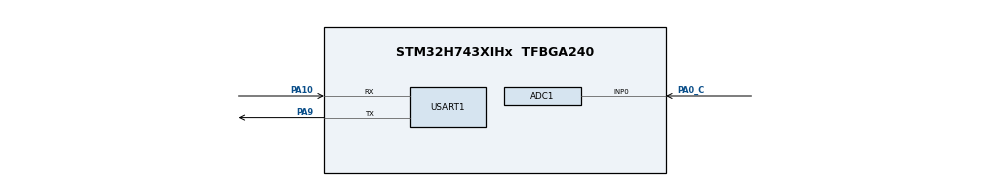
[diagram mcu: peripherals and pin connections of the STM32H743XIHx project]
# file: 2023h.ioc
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ADC1.Channel-1\#ChannelRegularConversion=ADC_CHANNEL_0
ADC1.ConversionDataManagement=ADC_CONVERSIONDATA_DMA_CIRCULAR
ADC1.ExternalTrigConv=ADC_EXTERNALTRIG_T6_TRGO
ADC1.NbrOfConversionFlag=1
ADC1.OffsetNumber-1\#ChannelRegularConversion=ADC_OFFSET_NONE
ADC1.OffsetSignedSaturation-1\#ChannelRegularConversion=DISABLE
ADC1.Overrun=ADC_OVR_DATA_OVERWRITTEN
ADC1.Rank-1\#ChannelRegularConversion=1
ADC1.SamplingTime-1\#ChannelRegularConversion=ADC_SAMPLETIME_1CYCLE_5
ADC1.master=1
CORTEX_M7.default_mode_Activation=1
Dma.ADC1.0.Direction=DMA_PERIPH_TO_MEMORY
Dma.ADC1.0.EventEnable=DISABLE
Dma.ADC1.0.FIFOMode=DMA_FIFOMODE_DISABLE
Dma.ADC1.0.Instance=DMA1_Stream0
Dma.ADC1.0.MemDataAlignment=DMA_MDATAALIGN_HALFWORD
Dma.ADC1.0.MemInc=DMA_MINC_ENABLE
Dma.ADC1.0.Mode=DMA_CIRCULAR
Dma.ADC1.0.PeriphDataAlignment=DMA_PDATAALIGN_HALFWORD
Dma.ADC1.0.PeriphInc=DMA_PINC_DISABLE
Dma.ADC1.0.Polarity=HAL_DMAMUX_REQ_GEN_RISING
Dma.ADC1.0.Priority=DMA_PRIORITY_LOW
Dma.ADC1.0.RequestNumber=1
Dma.ADC1.0.SignalID=NONE
Dma.ADC1.0.SyncEnable=DISABLE
Dma.ADC1.0.SyncPolarity=HAL_DMAMUX_SYNC_NO_EVENT
Dma.ADC1.0.SyncRequestNumber=1
Dma.ADC1.0.SyncSignalID=NONE
Dma.Request0=ADC1
Mcu.Family=STM32H7
Mcu.Name=STM32H743XIHx
Mcu.Package=TFBGA240
NVIC.ADC_IRQn=true\:0\:0\:false\:false\:true\:true\:true\:true
NVIC.DMA1_Stream0_IRQn=true\:0\:0\:false\:false\:true\:false\:true\:true
NVIC.PriorityGroup=NVIC_PRIORITYGROUP_4
NVIC.USART1_IRQn=true\:0\:0\:false\:false\:true\:true\:true\:true
PA0_C.Signal=SharedAnalog_PA0
PA10.Mode=Asynchronous
PA10.Signal=USART1_RX
PA9.Mode=Asynchronous
PA9.Signal=USART1_TX
PC14-OSC32_IN\ (OSC32_IN).Mode=LSE-External-Oscillator
PC14-OSC32_IN\ (OSC32_IN).Signal=RCC_OSC32_IN
PC15-OSC32_OUT\ (OSC32_OUT).Mode=LSE-External-Oscillator
PC15-OSC32_OUT\ (OSC32_OUT).Signal=RCC_OSC32_OUT
PH0-OSC_IN\ (PH0).Mode=HSE-External-Oscillator
PH0-OSC_IN\ (PH0).Signal=RCC_OSC_IN
PH1-OSC_OUT\ (PH1).Mode=HSE-External-Oscillator
PH1-OSC_OUT\ (PH1).Signal=RCC_OSC_OUT
ProjectManager.HeapSize=0x200
ProjectManager.StackSize=0x400
ProjectManager.TargetToolchain=MDK-ARM V5.32
RCC.ADCFreq_Value=72000000
RCC.APB1Freq_Value=120000000
RCC.APB2Freq_Value=120000000
RCC.APB3Freq_Value=120000000
RCC.APB4Freq_Value=120000000
RCC.CortexFreq_Value=480000000
RCC.D1PPRE=RCC_APB3_DIV2
RCC.D2PPRE1=RCC_APB1_DIV2
RCC.D2PPRE2=RCC_APB2_DIV2
RCC.D3PPRE=RCC_APB4_DIV2
RCC.DIVM1=4
RCC.DIVM2=4
RCC.DIVN1=60
RCC.DIVN2=18
RCC.DIVP2=4
RCC.HCLKFreq_Value=240000000
RCC.HPRE=RCC_HCLK_DIV2
RCC.PLL2FRACN=0
RCC.PLL3FRACN=0
RCC.PLLFRACN=0
RCC.SYSCLKFreq_VALUE=480000000
RCC.SYSCLKSource=RCC_SYSCLKSOURCE_PLLCLK
RCC.USBFreq_Value=480000000
SH.SharedAnalog_PA0.0=ADC1_INN1
SH.SharedAnalog_PA0.1=ADC1_INP0,IN0-Single-Ended
STMicroelectronics.X-CUBE-ALGOBUILD.1.4.0.LibraryCcDSPOoLibraryJjDSPOoLibrary=true
TIM6.Period=5-1
TIM6.Prescaler=24-1
TIM6.TIM_MasterOutputTrigger=TIM_TRGO_UPDATE
USART1.VirtualMode-Asynchronous=VM_ASYNC
VP_MEMORYMAP_VS_MEMORYMAP.Mode=CurAppReg
VP_STMicroelectronics.X-CUBE-ALGOBUILD_VS_DSPOoLibraryJjLibrary_1.4.0_1.4.0.Mode=DSPOoLibraryJjLibrary
VP_TIM6_VS_ClockSourceINT.Mode=Enable_Timer
board=custom

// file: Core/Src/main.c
/* USER CODE BEGIN Header */
/**
  ******************************************************************************
  * @file           : main.c
  * @brief          : Main program body
  ******************************************************************************
  * @attention
  *
  * Copyright (c) 2025 STMicroelectronics.
  * All rights reserved.
  *
  * This software is licensed under terms that can be found in the LICENSE file
  * in the root directory of this software component.
  * If no LICENSE file comes with this software, it is provided AS-IS.
  *
  ******************************************************************************
  */
/* USER CODE END Header */
#include "main.h"
#include "adc.h"
#include "dma.h"
#include "memorymap.h"
#include "tim.h"
#include "usart.h"
#include "gpio.h"

/* USER CODE BEGIN Includes */
#include "BSP.h"

#include "judge.h"

#include "math.h"
#include "arm_math.h"
#include "arm_const_structs.h"
/* USER CODE END Includes */

/* USER CODE BEGIN PD */
uint8_t rx_data;

volatile uint8_t adc_flag = 0,adc_cpltflag = 0;

float Window[ADC_SAMPLE_LEN] = {0};//

volatile uint16_t tim6_psc = 0;    //

arm_cfft_radix4_instance_f32 scfft;//定义scfft结构体
float FFT_InputBuf[ADC_SAMPLE_LEN*2];	//FFT输入数组�
float FFT_OutputBuf[ADC_SAMPLE_LEN];	//FFT输出数组

static uint16_t ADC_Value_DMA[ADC_SAMPLE_LEN+ADC_FAULTSAMPLE_LEN] = {0};//包含坏值的adc采样
uint16_t* valid_data_start = NULL;          // 有效数据起始指针

float basewave_value = 0;					//基波幅值
uint16_t basewave_index = 0;			//基波索引

uint16_t wavepeak_index[wave_counter_max] = {0};//波峰索引数组
uint8_t wavepeak_counter = 0;// 波峰索引个数

float value_peak[wave_counter_max] = {0};//波峰（拟合后）
//float value_peak_sort[wave_counter_max] = {0};//波峰（排序后）

uint32_t freq_1 = 0,freq_2 = 0;

/* USER CODE END PD */

void SystemClock_Config(void);
static void MPU_Config(void);

/* USER CODE BEGIN 0 */
//结构体排序
int compare_wavepeak(const void *a, const void *b) {
    wavepeak *peakA = (wavepeak *)a;
    wavepeak *peakB = (wavepeak *)b;

    if (peakA->value_peak_s < peakB->value_peak_s) return 1;   // 降序排序
    if (peakA->value_peak_s > peakB->value_peak_s) return -1;
    return 0;
}

/* USER CODE END 0 */

int main(void)
{

  /* MPU Configuration--------------------------------------------------------*/
  MPU_Config();

  /* MCU Configuration--------------------------------------------------------*/

  /* Reset of all peripherals, Initializes the Flash interface and the Systick. */
  HAL_Init();

  /* Configure the system clock */
  SystemClock_Config();

  /* Initialize all configured peripherals */
  MX_GPIO_Init();
  MX_DMA_Init();
  MX_ADC1_Init();
  MX_TIM6_Init();
  MX_USART1_UART_Init();
  /* USER CODE BEGIN 2 */
	Hanning_Win(ADC_SAMPLE_LEN ,Window);
	HAL_UART_Receive_IT(&huart1,&rx_data,1);
	HAL_ADCEx_Calibration_Start(my_hadc,ADC_CALIB_OFFSET,ADC_SINGLE_ENDED);
	HAL_Delay(10);
	printf("init OK\r\n");
  /* USER CODE END 2 */

  /* Infinite loop */
  while (1)
  {

    /* USER CODE BEGIN 3 */
		if(adc_flag)
		{
			adc_flag = 0;
			//采集ADC_SAMPLE_LEN+ADC_FAULTSAMPLE_LEN个数据
			adc1_tim6_getdata_4M((uint32_t *)ADC_Value_DMA,ADC_SAMPLE_LEN+ADC_FAULTSAMPLE_LEN);

			//等待采样完成
			while(!adc_cpltflag){};

			//用指针去除前ADC_FAULTSAMPLE_LEN个坏值
			valid_data_start = &ADC_Value_DMA[ADC_FAULTSAMPLE_LEN];
			adc_cpltflag = 0;
			//for(int i=ADC_FAULTSAMPLE_LEN;i<ADC_SAMPLE_LEN+ADC_FAULTSAMPLE_LEN;i++) printf("adc1=%d,",ADC_Value_DMA[i]);//√correct

			//4096个点的fft计算
			FFT_Calcular_win(Window,FFT_InputBuf,FFT_OutputBuf,valid_data_start);
			//for(int i=0;i<ADC_SAMPLE_LEN/2;i++) printf("adc1=%f,",FFT_OutputBuf[i]);

			//hanning窗函数检验
		  //for(int i=0;i<ADC_SAMPLE_LEN;i++)printf("adc1=%f,",Window[i]);√correct

			//获取基波幅值和索引
		  baseFreq_index(FFT_OutputBuf,ADC_SAMPLE_LEN,&basewave_value,&basewave_index);
			//printf("\r\nbasewave_value=%f,basewave_index=%d",basewave_value,basewave_index);//√correct

			//波峰索引和个数获取
			waveindex_get(FFT_OutputBuf,wavepeak_index,&wavepeak_counter,&basewave_value);
			//for(int i = 0;i<wavepeak_counter;i++) printf("\r\n%d",wavepeak_index[i]);//√correct

			//能量重心矫正峰值
			value_peak_corr(value_peak,wavepeak_counter,FFT_OutputBuf,wavepeak_index);

			//定义长度可变的结构体并赋值（绑定索引和相应幅值）
			wavepeak wavepeak_1[wavepeak_counter];
			for(int i = 0;i<wavepeak_counter;i++)
				{
					wavepeak_1[i].wavepeak_index_s = wavepeak_index [i];
					wavepeak_1[i].value_peak_s = value_peak[i];
					//printf("wavepeak_index_s=%d\r\n value_peak_s=%f\r\n",wavepeak_1[i].wavepeak_index_s,wavepeak_1[i].value_peak_s);//correct
				}
				//结构体排序
				qsort(wavepeak_1, wavepeak_counter, sizeof(wavepeak), compare_wavepeak);
//				for(int i = 0;i<wavepeak_counter;i++)
				//验证排序
//					printf("wavepeak_index_s=%d\r\n value_peak_s=%f\r\n",wavepeak_1[i].wavepeak_index_s,wavepeak_1[i].value_peak_s);//correct

				//计算两峰值比
				float  rata = wavepeak_1[1].value_peak_s / wavepeak_1[0].value_peak_s;
					printf("rata=%f\r\n",rata);
/****************************************************************模板分界线************************************************************************/

				analyzeWavePeaks(rata,wavepeak_counter,wavepeak_1,value_peak);
				//波形识别&计算频率（频率高于100k识别不准）
		}

  }
  /* USER CODE END 3 */
}

void SystemClock_Config(void)
{
  RCC_OscInitTypeDef RCC_OscInitStruct = {0};
  RCC_ClkInitTypeDef RCC_ClkInitStruct = {0};

  /** Supply configuration update enable
  */
  HAL_PWREx_ConfigSupply(PWR_LDO_SUPPLY);

  /** Configure the main internal regulator output voltage
  */
  __HAL_PWR_VOLTAGESCALING_CONFIG(PWR_REGULATOR_VOLTAGE_SCALE0);

  while(!__HAL_PWR_GET_FLAG(PWR_FLAG_VOSRDY)) {}

  /** Initializes the RCC Oscillators according to the specified parameters
  * in the RCC_OscInitTypeDef structure.
  */
  RCC_OscInitStruct.OscillatorType = RCC_OSCILLATORTYPE_HSI;
  RCC_OscInitStruct.HSIState = RCC_HSI_DIV1;
  RCC_OscInitStruct.HSICalibrationValue = RCC_HSICALIBRATION_DEFAULT;
  RCC_OscInitStruct.PLL.PLLState = RCC_PLL_ON;
  RCC_OscInitStruct.PLL.PLLSource = RCC_PLLSOURCE_HSI;
  RCC_OscInitStruct.PLL.PLLM = 4;
  RCC_OscInitStruct.PLL.PLLN = 60;
  RCC_OscInitStruct.PLL.PLLP = 2;
  RCC_OscInitStruct.PLL.PLLQ = 2;
  RCC_OscInitStruct.PLL.PLLR = 2;
  RCC_OscInitStruct.PLL.PLLRGE = RCC_PLL1VCIRANGE_3;
  RCC_OscInitStruct.PLL.PLLVCOSEL = RCC_PLL1VCOWIDE;
  RCC_OscInitStruct.PLL.PLLFRACN = 0;
  if (HAL_RCC_OscConfig(&RCC_OscInitStruct) != HAL_OK)
  {
    Error_Handler();
  }

  /** Initializes the CPU, AHB and APB buses clocks
  */
  RCC_ClkInitStruct.ClockType = RCC_CLOCKTYPE_HCLK|RCC_CLOCKTYPE_SYSCLK
                              |RCC_CLOCKTYPE_PCLK1|RCC_CLOCKTYPE_PCLK2
                              |RCC_CLOCKTYPE_D3PCLK1|RCC_CLOCKTYPE_D1PCLK1;
  RCC_ClkInitStruct.SYSCLKSource = RCC_SYSCLKSOURCE_PLLCLK;
  RCC_ClkInitStruct.SYSCLKDivider = RCC_SYSCLK_DIV1;
  RCC_ClkInitStruct.AHBCLKDivider = RCC_HCLK_DIV2;
  RCC_ClkInitStruct.APB3CLKDivider = RCC_APB3_DIV2;
  RCC_ClkInitStruct.APB1CLKDivider = RCC_APB1_DIV2;
  RCC_ClkInitStruct.APB2CLKDivider = RCC_APB2_DIV2;
  RCC_ClkInitStruct.APB4CLKDivider = RCC_APB4_DIV2;

  if (HAL_RCC_ClockConfig(&RCC_ClkInitStruct, FLASH_LATENCY_4) != HAL_OK)
  {
    Error_Handler();
  }
}

/* USER CODE BEGIN 4 */
void HAL_ADC_ConvCpltCallback(ADC_HandleTypeDef *hadc)
{
	//HAL_ADC_Stop_DMA(&hadc1);
	HAL_TIM_Base_Stop(&htim6);
	adc_cpltflag ++;
}
void HAL_UART_RxCpltCallback(UART_HandleTypeDef *huart)
{
	if(huart == &huart1)
	{
		if(rx_data == '1')
			adc_flag = 1;
	}

	HAL_UART_Receive_IT(&huart1,&rx_data,1);
}

/* USER CODE END 4 */

 /* MPU Configuration */

void MPU_Config(void)
{
  MPU_Region_InitTypeDef MPU_InitStruct = {0};

  /* Disables the MPU */
  HAL_MPU_Disable();

  /** Initializes and configures the Region and the memory to be protected
  */
  MPU_InitStruct.Enable = MPU_REGION_ENABLE;
  MPU_InitStruct.Number = MPU_REGION_NUMBER0;
  MPU_InitStruct.BaseAddress = 0x0;
  MPU_InitStruct.Size = MPU_REGION_SIZE_4GB;
  MPU_InitStruct.SubRegionDisable = 0x87;
  MPU_InitStruct.TypeExtField = MPU_TEX_LEVEL0;
  MPU_InitStruct.AccessPermission = MPU_REGION_NO_ACCESS;
  MPU_InitStruct.DisableExec = MPU_INSTRUCTION_ACCESS_DISABLE;
  MPU_InitStruct.IsShareable = MPU_ACCESS_SHAREABLE;
  MPU_InitStruct.IsCacheable = MPU_ACCESS_NOT_CACHEABLE;
  MPU_InitStruct.IsBufferable = MPU_ACCESS_NOT_BUFFERABLE;

  HAL_MPU_ConfigRegion(&MPU_InitStruct);
  /* Enables the MPU */
  HAL_MPU_Enable(MPU_PRIVILEGED_DEFAULT);

}

void Error_Handler(void)
{
  __disable_irq();
  while (1)
  {
  }
}
